AUTOSAR XML (schema 4-2-2)
package /AUTOLIV/SoftwareComponents/ERH
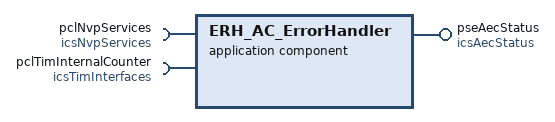
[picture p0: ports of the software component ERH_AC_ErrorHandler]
  application sw component type ERH_AC_ErrorHandler: category=SWC
    require port pclNvpServices: required-com-specs=[ReadBlock, WriteBlock, EraseNvBlock, NotifyBlockStatusChanged, ReadAddress, WriteAddress, EraseAddress], required-interface=icsNvpServices
    require port pclTimInternalCounter: client-com-spec=GetInternalCounter, required-interface=icsTimInterfaces
    provide port pseAecStatus: provided-interface=icsAecStatus
      provided-com-specs:
        operation=GetAecStatus, queue-length=1
        operation=SetAecEvent, queue-length=1
        operation=GetAecGroupsStatus, queue-length=1
        operation=GetNumberOfImplementedAec, queue-length=1
        operation=GetAecNvpBlockRecordingStatus, queue-length=1
